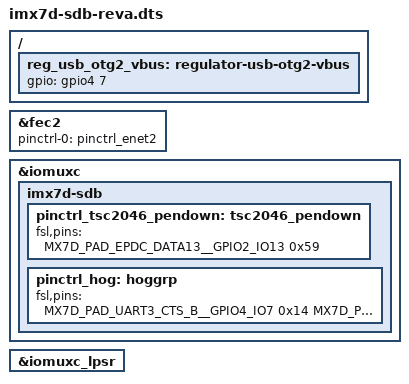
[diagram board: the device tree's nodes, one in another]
// SPDX-License-Identifier: GPL-2.0+ OR MIT
//
// Copyright (C) 2015 Freescale Semiconductor, Inc.

/dts-v1/;

#include "imx7d-sdb.dts"

/ {
	reg_usb_otg2_vbus: regulator-usb-otg2-vbus {
		gpio = <&gpio4 7 GPIO_ACTIVE_HIGH>;
	};
};

&fec2 {
	pinctrl-0 = <&pinctrl_enet2>;
	/delete-property/pinctrl-assert-gpios;
};

&iomuxc {
	imx7d-sdb {
		pinctrl_tsc2046_pendown: tsc2046_pendown {
			fsl,pins = <
				MX7D_PAD_EPDC_DATA13__GPIO2_IO13	0x59
			>;
		};

		pinctrl_hog: hoggrp {
			fsl,pins = <
				MX7D_PAD_UART3_CTS_B__GPIO4_IO7		0x14
				MX7D_PAD_ECSPI2_SS0__GPIO4_IO23		0x34  /* bt reg on */
			>;
		};
	};
};

&iomuxc_lpsr {
	/delete-property/pinctrl-names;
	/delete-property/pinctrl-0;
};
